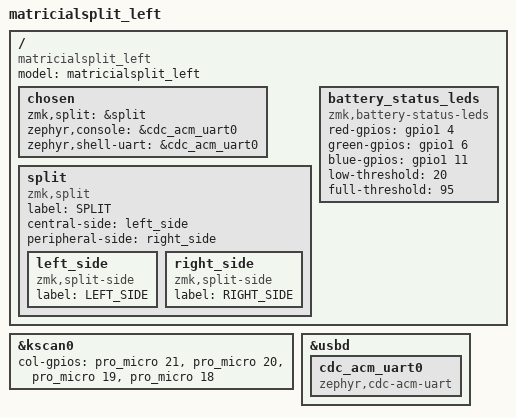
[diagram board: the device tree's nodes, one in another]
/*
 * Copyright (c) 2020 The ZMK Contributors
 *
 * SPDX-License-Identifier: MIT
 */

#include "matricialsplit.dtsi"

/ {
    model = "matricialsplit_left";
    compatible = "matricialsplit_left";

    chosen {
        zmk,split = &split;
        zephyr,console = &cdc_acm_uart0;
        zephyr,shell-uart = &cdc_acm_uart0;
    };

    split: split {
        compatible = "zmk,split";
        label = "SPLIT";
        
        central-side = <&left_side>;
        peripheral-side = <&right_side>;
        
        left_side: left_side {
            compatible = "zmk,split-side";
            label = "LEFT_SIDE";
        };
        
        right_side: right_side {
            compatible = "zmk,split-side";
            label = "RIGHT_SIDE";
        };
    };
};

&kscan0 {
    col-gpios
        = <&pro_micro 21 (GPIO_ACTIVE_HIGH | GPIO_PULL_DOWN)>
        , <&pro_micro 20 (GPIO_ACTIVE_HIGH | GPIO_PULL_DOWN)>
        , <&pro_micro 19 (GPIO_ACTIVE_HIGH | GPIO_PULL_DOWN)>
        , <&pro_micro 18 (GPIO_ACTIVE_HIGH | GPIO_PULL_DOWN)>
        ;
};

/ {
    /*
     * Nodo principal del indicador de batería
     * - Node name: battery_status_leds (para referencia interna)
     * - Label: battery_status_leds (para poder referenciar con &battery_status_leds)
     * - Compatible: le dice a ZMK que driver usar
     */
    battery_status_leds: battery_status_leds {
        compatible = "zmk,battery-status-leds";
        status = "okay";  // Explícitamente habilitado (opt-in)
        
        /*
         * Configuración de pines GPIO
         * Formato: <&controlador pin flags>
         * - &gpio1: Puerto GPIO 1 del nRF52840
         * - Números: P1.04, P1.06, P1.11 según tu selección
         * - GPIO_ACTIVE_HIGH: LED se enciende con señal alta
         */
        red-gpios = <&gpio1 4 GPIO_ACTIVE_HIGH>;     // P1.04 - LED rojo
        green-gpios = <&gpio1 6 GPIO_ACTIVE_HIGH>;   // P1.06 - LED verde  
        blue-gpios = <&gpio1 11 GPIO_ACTIVE_HIGH>;   // P1.11 - LED azul
        
        /*
         * Configuración de umbrales (opcional)
         * Si se omiten, se usan los defaults (20 y 95)
         * Estos valores serán validados en compilación
         */
        low-threshold = <20>;   // Batería baja: menor a 20%
        full-threshold = <95>;  // Batería cargada: mayor o igual a 95%
    };
};

// Habilita CDC ACM para USB logging
&usbd {
    status = "okay";
    cdc_acm_uart0: cdc_acm_uart0 {
        compatible = "zephyr,cdc-acm-uart";
    };
};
